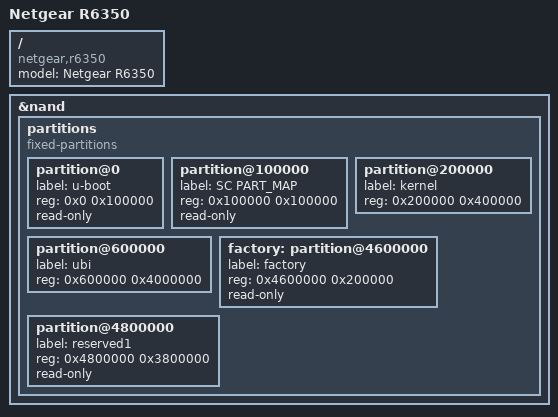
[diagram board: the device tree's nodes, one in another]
// SPDX-License-Identifier: GPL-2.0-only

#include "mt7621_netgear_sercomm_chj.dtsi"

/ {
	compatible = "netgear,r6350", "mediatek,mt7621-soc";
	model = "Netgear R6350";
};

&nand {
	status = "okay";

	partitions {
		compatible = "fixed-partitions";
		#address-cells = <1>;
		#size-cells = <1>;

		partition@0 {
			label = "u-boot";
			reg = <0x0 0x100000>;
			read-only;
		};

		partition@100000 {
			label = "SC PART_MAP";
			reg = <0x100000 0x100000>;
			read-only;
		};

		partition@200000 {
			label = "kernel";
			reg = <0x200000 0x400000>;
		};

		partition@600000 {
			label = "ubi";
			reg = <0x600000 0x4000000>;
		};

		factory: partition@4600000 {
			label = "factory";
			reg = <0x4600000 0x200000>;
			read-only;
		};

		partition@4800000 {
			label = "reserved1";
			reg = <0x4800000 0x3800000>;
			read-only;
		};
	};
};
